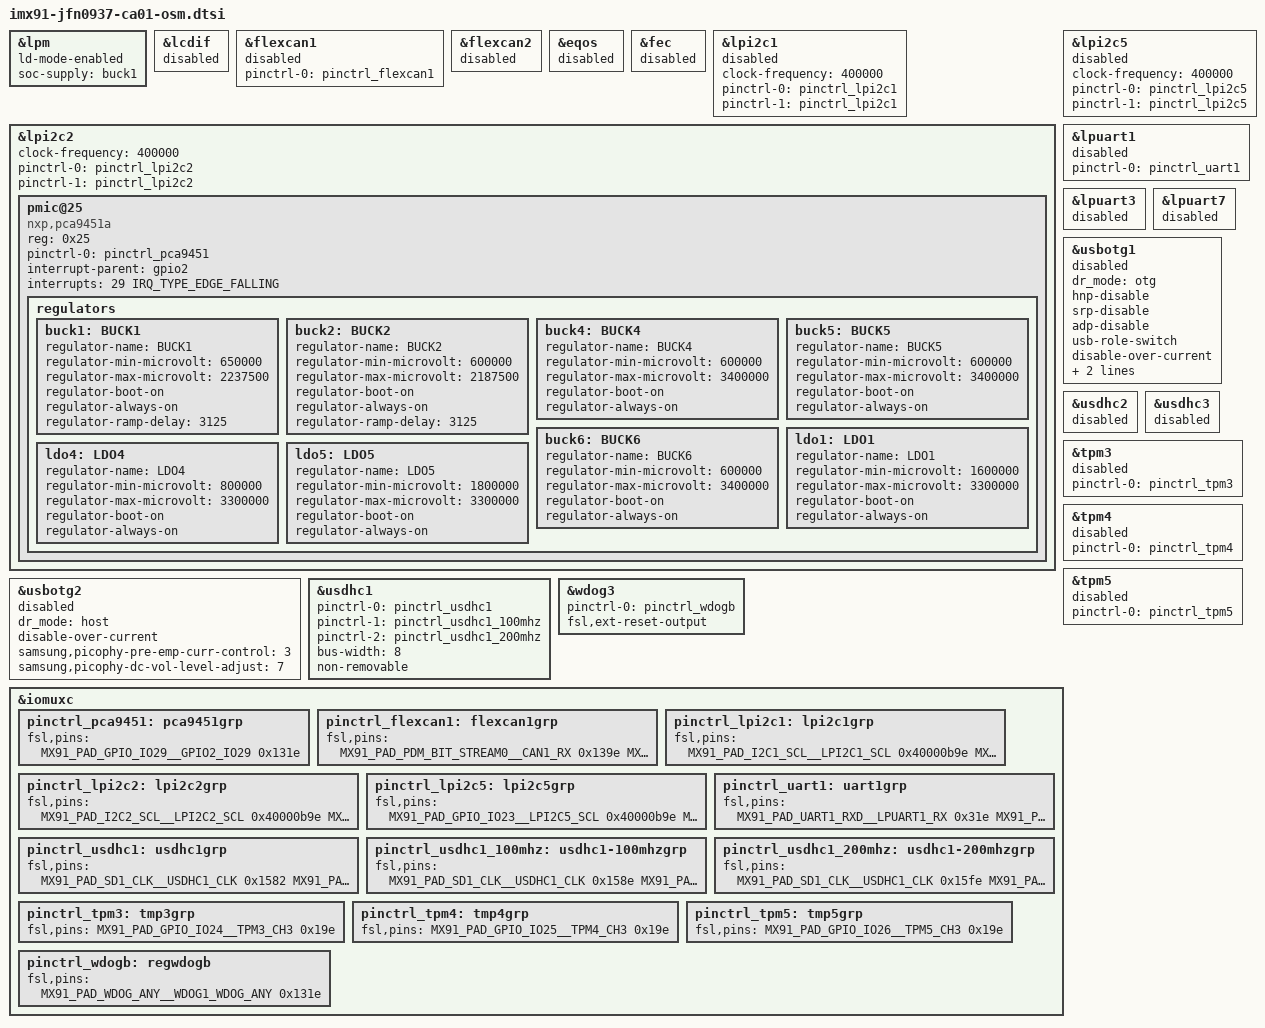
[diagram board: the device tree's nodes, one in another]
/*
 * Copyright 2026 MASELETTRONICA
 */

#include <dt-bindings/usb/pd.h>

/ {

};


&lpm {
	ld-mode-enabled;
	soc-supply = <&buck1>;
	status = "okay";
};

//=============================================================================
//=== LCDIF
//=============================================================================
&lcdif {
	status = "disabled";
};

//=============================================================================
//=== CAN1
//=============================================================================
&flexcan1 {
	pinctrl-names = "default";
	pinctrl-0 = <&pinctrl_flexcan1>;
	status = "disabled";
};

//=============================================================================
//=== CAN2
//=============================================================================
&flexcan2 {
	status = "disabled";
};

//=============================================================================
//=== EQOS
//=============================================================================
&eqos {
	status = "disabled";
};

//=============================================================================
//=== FEC
//=============================================================================
&fec {
	status = "disabled";
};

//=============================================================================
//=== I2C1
//=============================================================================
&lpi2c1 {
	#address-cells = <1>;
	#size-cells = <0>;
	clock-frequency = <400000>;
	pinctrl-names = "default","sleep";
	pinctrl-0 = <&pinctrl_lpi2c1>;
	pinctrl-1 = <&pinctrl_lpi2c1>;
	status = "disabled";	
};

//=============================================================================
//=== I2C2
//=============================================================================
&lpi2c2 {
	#address-cells = <1>;
	#size-cells = <0>;
	clock-frequency = <400000>;
	pinctrl-names = "default", "sleep";
	pinctrl-0 = <&pinctrl_lpi2c2>;
	pinctrl-1 = <&pinctrl_lpi2c2>;
	status = "okay";

	pmic@25 {
		compatible = "nxp,pca9451a";
		reg = <0x25>;
		pinctrl-names = "default";
		pinctrl-0 = <&pinctrl_pca9451>;
		interrupt-parent = <&gpio2>;
		interrupts = <29 IRQ_TYPE_EDGE_FALLING>;

		regulators {
			buck1: BUCK1 {
				regulator-name = "BUCK1";
				regulator-min-microvolt = <650000>;
				regulator-max-microvolt = <2237500>;
				regulator-boot-on;
				regulator-always-on;
				regulator-ramp-delay = <3125>;
			};

			buck2: BUCK2 {
				regulator-name = "BUCK2";
				regulator-min-microvolt = <600000>;
				regulator-max-microvolt = <2187500>;
				regulator-boot-on;
				regulator-always-on;
				regulator-ramp-delay = <3125>;
			};

			buck4: BUCK4{
				regulator-name = "BUCK4";
				regulator-min-microvolt = <600000>;
				regulator-max-microvolt = <3400000>;
				regulator-boot-on;
				regulator-always-on;
			};

			buck5: BUCK5{
				regulator-name = "BUCK5";
				regulator-min-microvolt = <600000>;
				regulator-max-microvolt = <3400000>;
				regulator-boot-on;
				regulator-always-on;
			};

			buck6: BUCK6 {
				regulator-name = "BUCK6";
				regulator-min-microvolt = <600000>;
				regulator-max-microvolt = <3400000>;
				regulator-boot-on;
				regulator-always-on;
			};

			ldo1: LDO1 {
				regulator-name = "LDO1";
				regulator-min-microvolt = <1600000>;
				regulator-max-microvolt = <3300000>;
				regulator-boot-on;
				regulator-always-on;
			};

			ldo4: LDO4 {
				regulator-name = "LDO4";
				regulator-min-microvolt = <800000>;
				regulator-max-microvolt = <3300000>;
				regulator-boot-on;
				regulator-always-on;
			};

			ldo5: LDO5 {
				regulator-name = "LDO5";
				regulator-min-microvolt = <1800000>;
				regulator-max-microvolt = <3300000>;
				regulator-boot-on;
				regulator-always-on;
			};
		};
	};

};

//=============================================================================
//=== I2C5
//=============================================================================
&lpi2c5 {
	#address-cells = <1>;
	#size-cells = <0>;
	clock-frequency = <400000>;
	pinctrl-names = "default","sleep";
	pinctrl-0 = <&pinctrl_lpi2c5>;
	pinctrl-1 = <&pinctrl_lpi2c5>;
	status = "disabled";	
};

//=============================================================================
//=== UART1 console
//=============================================================================
&lpuart1 { /* console */
	pinctrl-names = "default";
	pinctrl-0 = <&pinctrl_uart1>;
	status = "disabled";
};

//=============================================================================
//=== UART3 RS232/RS485
//=============================================================================
&lpuart3 { 
	status = "disabled";
};

//=============================================================================
//=== UART7 RS232/RS485
//=============================================================================
&lpuart7 { 
	status = "disabled";
};

//=============================================================================
//=== USB2 otg
//=============================================================================
&usbotg1 {
	dr_mode = "otg";
	hnp-disable;
	srp-disable;
	adp-disable;
	usb-role-switch;
	disable-over-current;
	samsung,picophy-pre-emp-curr-control = <3>;
	samsung,picophy-dc-vol-level-adjust = <7>;
	status = "disabled";
};

//=============================================================================
//=== USB2 host
//=============================================================================
&usbotg2 {
	dr_mode = "host";
	disable-over-current;
	samsung,picophy-pre-emp-curr-control = <3>;
	samsung,picophy-dc-vol-level-adjust = <7>;
	status = "disabled";
};

//=============================================================================
//=== USDHC1 eMMC
//=============================================================================
&usdhc1 {
	pinctrl-names = "default", "state_100mhz", "state_200mhz";
	pinctrl-0 = <&pinctrl_usdhc1>;
	pinctrl-1 = <&pinctrl_usdhc1_100mhz>;
	pinctrl-2 = <&pinctrl_usdhc1_200mhz>;
	bus-width = <8>;
	non-removable;
	status = "okay";
};

//=============================================================================
//=== USDHC2 uSD
//=============================================================================
&usdhc2 {
	status = "disabled";
};

//=============================================================================
//=== USDHC3
//=============================================================================
&usdhc3 {
	status = "disabled";
};

//=============================================================================
//=== TPM3
//=============================================================================
&tpm3 {
	pinctrl-names = "default";
	pinctrl-0 = <&pinctrl_tpm3>;
	status = "disabled";
};

//=============================================================================
//=== TPM4
//=============================================================================
&tpm4 {
	pinctrl-names = "default";
	pinctrl-0 = <&pinctrl_tpm4>;
	status = "disabled";
};

//=============================================================================
//=== TPM5
//=============================================================================
&tpm5 {
	pinctrl-names = "default";
	pinctrl-0 = <&pinctrl_tpm5>;
	status = "disabled";
};

//=============================================================================
//=== WDOG3
//=============================================================================
&wdog3 {
	pinctrl-names = "default";
	pinctrl-0 = <&pinctrl_wdogb>;
	fsl,ext-reset-output;
	status = "okay";
};




//=============================================================================
//#############################################################################
//=== PINMUX
//#############################################################################
//=============================================================================
&iomuxc {

	pinctrl_pca9451: pca9451grp {
		fsl,pins = <
			MX91_PAD_GPIO_IO29__GPIO2_IO29								0x131e
		>;
	};

	pinctrl_flexcan1: flexcan1grp {
		fsl,pins = <
		    MX91_PAD_PDM_BIT_STREAM0__CAN1_RX          					0x139e
            MX91_PAD_PDM_CLK__CAN1_TX									0x139e
		>;
	};

	pinctrl_lpi2c1: lpi2c1grp {
		fsl,pins = <
			MX91_PAD_I2C1_SCL__LPI2C1_SCL								0x40000b9e
			MX91_PAD_I2C1_SDA__LPI2C1_SDA								0x40000b9e
		>;
	};

	pinctrl_lpi2c2: lpi2c2grp {
		fsl,pins = <
			MX91_PAD_I2C2_SCL__LPI2C2_SCL								0x40000b9e
			MX91_PAD_I2C2_SDA__LPI2C2_SDA								0x40000b9e
		>;
	};

	pinctrl_lpi2c5: lpi2c5grp {
		fsl,pins = <
			MX91_PAD_GPIO_IO23__LPI2C5_SCL								0x40000b9e
			MX91_PAD_GPIO_IO22__LPI2C5_SDA								0x40000b9e
		>;
	};
	
	pinctrl_uart1: uart1grp {
		fsl,pins = <
			MX91_PAD_UART1_RXD__LPUART1_RX								0x31e
			MX91_PAD_UART1_TXD__LPUART1_TX								0x31e
		>;
	};

	/* need to config the SION for data and cmd pad, refer to ERR052021 */
	pinctrl_usdhc1: usdhc1grp {
		fsl,pins = <
			MX91_PAD_SD1_CLK__USDHC1_CLK								0x1582
			MX91_PAD_SD1_CMD__USDHC1_CMD								0x40001382
			MX91_PAD_SD1_DATA0__USDHC1_DATA0							0x40001382
			MX91_PAD_SD1_DATA1__USDHC1_DATA1							0x40001382
			MX91_PAD_SD1_DATA2__USDHC1_DATA2							0x40001382
			MX91_PAD_SD1_DATA3__USDHC1_DATA3							0x40001382
			MX91_PAD_SD1_DATA4__USDHC1_DATA4							0x40001382
			MX91_PAD_SD1_DATA5__USDHC1_DATA5							0x40001382
			MX91_PAD_SD1_DATA6__USDHC1_DATA6							0x40001382
			MX91_PAD_SD1_DATA7__USDHC1_DATA7							0x40001382
			MX91_PAD_SD1_STROBE__USDHC1_STROBE							0x1582
		>;
	};

	/* need to config the SION for data and cmd pad, refer to ERR052021 */
	pinctrl_usdhc1_100mhz: usdhc1-100mhzgrp {
		fsl,pins = <
			MX91_PAD_SD1_CLK__USDHC1_CLK								0x158e
			MX91_PAD_SD1_CMD__USDHC1_CMD								0x4000138e
			MX91_PAD_SD1_DATA0__USDHC1_DATA0							0x4000138e
			MX91_PAD_SD1_DATA1__USDHC1_DATA1							0x4000138e
			MX91_PAD_SD1_DATA2__USDHC1_DATA2							0x4000138e
			MX91_PAD_SD1_DATA3__USDHC1_DATA3							0x4000138e
			MX91_PAD_SD1_DATA4__USDHC1_DATA4							0x4000138e
			MX91_PAD_SD1_DATA5__USDHC1_DATA5							0x4000138e
			MX91_PAD_SD1_DATA6__USDHC1_DATA6							0x4000138e
			MX91_PAD_SD1_DATA7__USDHC1_DATA7							0x4000138e
			MX91_PAD_SD1_STROBE__USDHC1_STROBE							0x158e
		>;
	};

	/* need to config the SION for data and cmd pad, refer to ERR052021 */
	pinctrl_usdhc1_200mhz: usdhc1-200mhzgrp {
		fsl,pins = <
			MX91_PAD_SD1_CLK__USDHC1_CLK								0x15fe
			MX91_PAD_SD1_CMD__USDHC1_CMD								0x400013fe
			MX91_PAD_SD1_DATA0__USDHC1_DATA0							0x400013fe
			MX91_PAD_SD1_DATA1__USDHC1_DATA1							0x400013fe
			MX91_PAD_SD1_DATA2__USDHC1_DATA2							0x400013fe
			MX91_PAD_SD1_DATA3__USDHC1_DATA3							0x400013fe
			MX91_PAD_SD1_DATA4__USDHC1_DATA4							0x400013fe
			MX91_PAD_SD1_DATA5__USDHC1_DATA5							0x400013fe
			MX91_PAD_SD1_DATA6__USDHC1_DATA6							0x400013fe
			MX91_PAD_SD1_DATA7__USDHC1_DATA7							0x400013fe
			MX91_PAD_SD1_STROBE__USDHC1_STROBE							0x15fe
		>;
	};

	pinctrl_tpm3: tmp3grp {
		fsl,pins = <
			MX91_PAD_GPIO_IO24__TPM3_CH3								0x19e
		>;
	};

	pinctrl_tpm4: tmp4grp {
		fsl,pins = <
			MX91_PAD_GPIO_IO25__TPM4_CH3								0x19e
		>;
	};

	pinctrl_tpm5: tmp5grp {
		fsl,pins = <
			MX91_PAD_GPIO_IO26__TPM5_CH3								0x19e
		>;
	};

	pinctrl_wdogb: regwdogb {
		fsl,pins = <
			MX91_PAD_WDOG_ANY__WDOG1_WDOG_ANY							0x131e
		>;
	};

};
